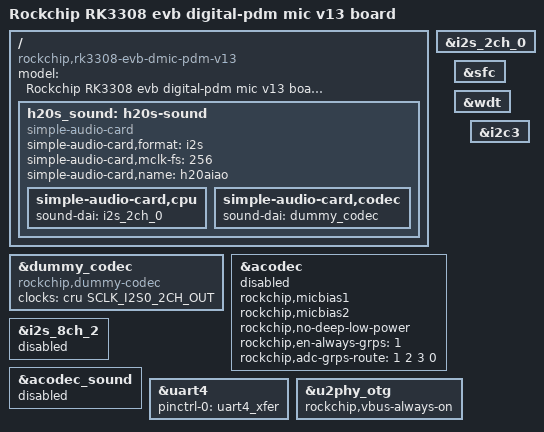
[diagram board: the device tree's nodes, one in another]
// SPDX-License-Identifier: (GPL-2.0+ OR MIT)
/*
 * Copyright (c) 2018 Fuzhou Rockchip Electronics Co., Ltd
 */

/dts-v1/;

#include "rk3308hs-h20.dtsi"

/ {
	model = "Rockchip RK3308 evb digital-pdm mic v13 board";
	compatible = "rockchip,rk3308-evb-dmic-pdm-v13", "rockchip,rk3308";
	
	h20s_sound: h20s-sound {
		status = "okay";
		compatible = "simple-audio-card";
		simple-audio-card,format = "i2s";
		simple-audio-card,mclk-fs = <256>;
		simple-audio-card,name = "h20aiao";

		simple-audio-card,cpu {
			sound-dai = <&i2s_2ch_0>;
		};
		simple-audio-card,codec {
			sound-dai = <&dummy_codec>;
		};
 	};
};

&i2s_2ch_0 {
	status = "okay";
	#sound-dai-cells = <0>;
};

&dummy_codec{
	status = "okay";
    compatible = "rockchip,dummy-codec";
    #sound-dai-cells = <0>;
    clocks = <&cru SCLK_I2S0_2CH_OUT>;
    clock-names = "mclk";
};

&acodec {
	status = "disable";
	rockchip,micbias1;
	rockchip,micbias2;
	rockchip,no-deep-low-power;
	rockchip,en-always-grps = <1>;
	rockchip,adc-grps-route = <1 2 3 0>;
};

&i2s_8ch_2 {
	status = "disable";
};

&acodec_sound {
	status = "disable";
};

&sfc {
	status = "okay";
};

&uart4 {
	status = "okay";
	pinctrl-names = "default";
	pinctrl-0 = <&uart4_xfer>;

};

&wdt {
	status = "okay";
};

&u2phy_otg {
	rockchip,vbus-always-on;
};

&i2c3 {
	status = "okay";
};
